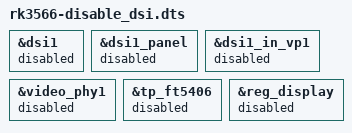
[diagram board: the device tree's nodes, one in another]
/dts-v1/;
/plugin/;

/ {
	// Disable DSI
	fragment@0 {
		target = <&dsi1>;
		__overlay__ {
			status = "disabled";
		};
	};

	fragment@1 {
		target = <&dsi1_panel>;
		__overlay__ {
			status = "disabled";
		};
	};

	fragment@2 {
		target = <&dsi1_in_vp1>;
		__overlay__ {
			status = "disabled";
		};
	};

	fragment@3 {
		target = <&video_phy1>;
		__overlay__ {
			status = "disabled";
		};
	};

	fragment@4 {
		target = <&tp_ft5406>;
		__overlay__ {
			status = "disabled";
		};
	};

	fragment@5 {
		target = <&reg_display>;
		__overlay__ {
			status = "disabled";
		};
	};
};
